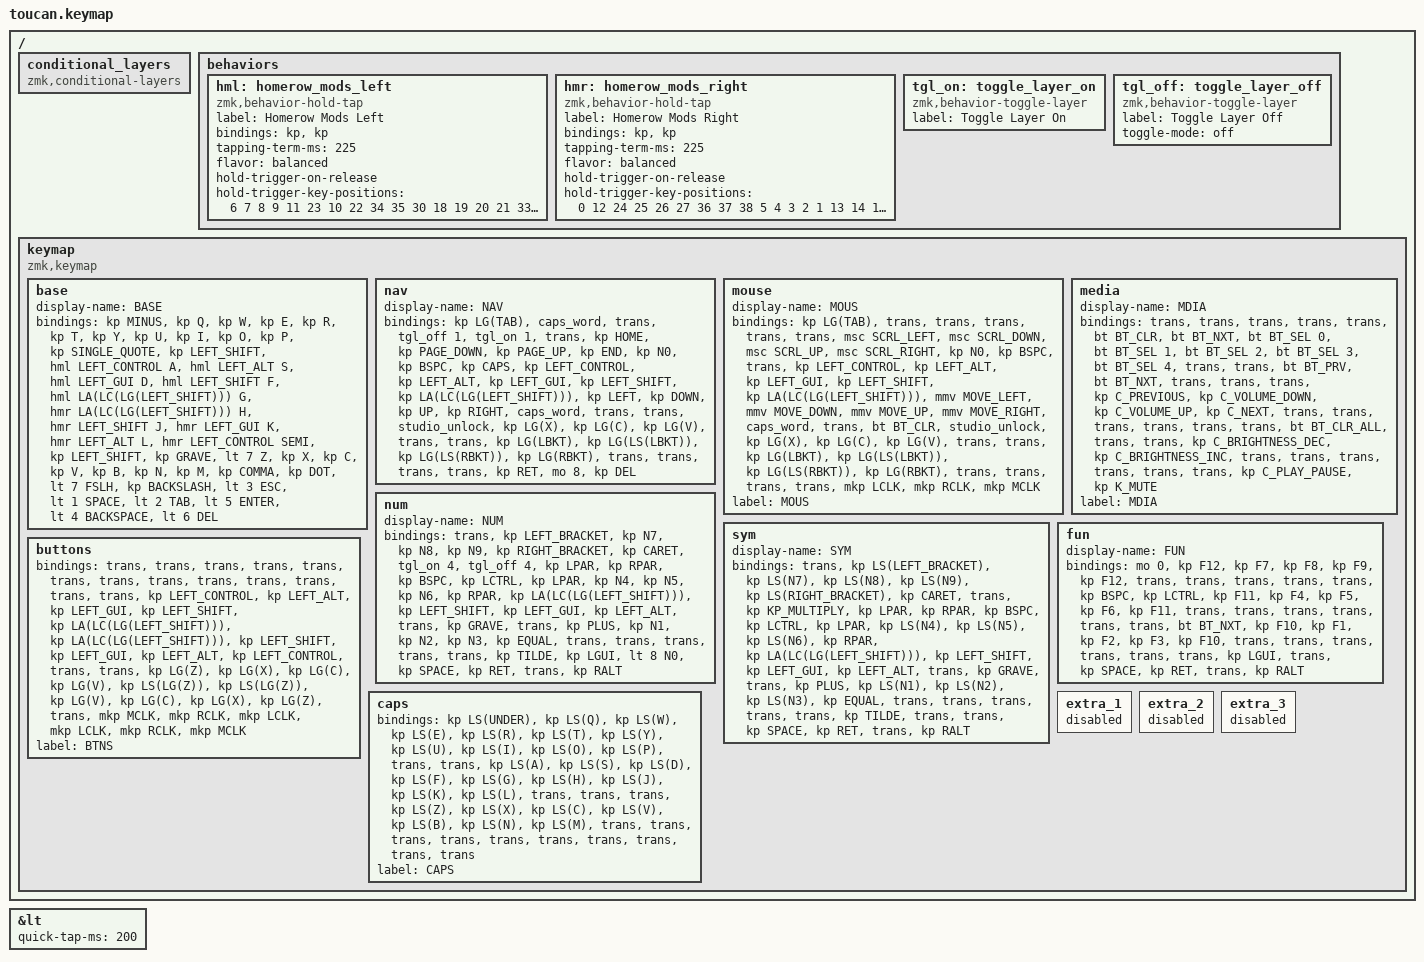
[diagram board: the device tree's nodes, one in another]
#include <behaviors.dtsi>
#include <dt-bindings/zmk/keys.h>
#include <dt-bindings/zmk/bt.h>
#include <dt-bindings/zmk/outputs.h>
#include <dt-bindings/zmk/pointing.h>

#define BASE 0
#define NAV  1
#define SYM  2
#define FUN  3

&lt {
    quick-tap-ms = <200>;
};

/ {
    conditional_layers { compatible = "zmk,conditional-layers"; };

    behaviors {
        hml: homerow_mods_left {
            compatible = "zmk,behavior-hold-tap";
            label = "Homerow Mods Left";
            bindings = <&kp>, <&kp>;

            #binding-cells = <2>;
            tapping-term-ms = <225>;
            flavor = "balanced";
            hold-trigger-on-release;
            hold-trigger-key-positions = <6 7 8 9 11 23 10 22 34 35 30 18 19 20 21 33 32 31 39 40 41 38 37>;
        };

        hmr: homerow_mods_right {
            compatible = "zmk,behavior-hold-tap";
            label = "Homerow Mods Right";
            bindings = <&kp>, <&kp>;

            #binding-cells = <2>;
            tapping-term-ms = <225>;
            flavor = "balanced";
            hold-trigger-on-release;
            hold-trigger-key-positions = <0 12 24 25 26 27 36 37 38 5 4 3 2 1 13 14 15 16 17 29 28>;
        };

        tgl_on: toggle_layer_on {
            compatible = "zmk,behavior-toggle-layer";
            label = "Toggle Layer On";
            #binding-cells = <1>;
        };

        tgl_off: toggle_layer_off {
            compatible = "zmk,behavior-toggle-layer";
            label = "Toggle Layer Off";
            #binding-cells = <1>;
            toggle-mode = "off";
        };
    };

    keymap {
        compatible = "zmk,keymap";

        base {
            display-name = "BASE";
            bindings = <
&kp MINUS  &kp Q  &kp W  &kp E  &kp R  &kp T  &kp Y  &kp U  &kp I  &kp O  &kp P  &kp SINGLE_QUOTE  &kp LEFT_SHIFT  &hml LEFT_CONTROL A  &hml LEFT_ALT S  &hml LEFT_GUI D  &hml LEFT_SHIFT F  &hml LA(LC(LG(LEFT_SHIFT))) G  &hmr LA(LC(LG(LEFT_SHIFT))) H  &hmr LEFT_SHIFT J  &hmr LEFT_GUI K  &hmr LEFT_ALT L  &hmr LEFT_CONTROL SEMI  &kp LEFT_SHIFT  &kp GRAVE  &lt 7 Z  &kp X  &kp C  &kp V  &kp B  &kp N  &kp M  &kp COMMA  &kp DOT  &lt 7 FSLH  &kp BACKSLASH  &lt 3 ESC  &lt 1 SPACE  &lt 2 TAB  &lt 5 ENTER  &lt 4 BACKSPACE  &lt 6 DEL
            >;
        };

        nav {
            display-name = "NAV";
            bindings = <
&kp LG(TAB)  &caps_word  &trans  &tgl_off 1  &tgl_on 1  &trans  &kp HOME  &kp PAGE_DOWN  &kp PAGE_UP  &kp END  &kp N0  &kp BSPC  &kp CAPS  &kp LEFT_CONTROL  &kp LEFT_ALT  &kp LEFT_GUI  &kp LEFT_SHIFT  &kp LA(LC(LG(LEFT_SHIFT)))  &kp LEFT  &kp DOWN  &kp UP  &kp RIGHT  &caps_word  &trans  &trans  &studio_unlock  &kp LG(X)  &kp LG(C)  &kp LG(V)  &trans  &trans  &kp LG(LBKT)  &kp LG(LS(LBKT))  &kp LG(LS(RBKT))  &kp LG(RBKT)  &trans  &trans  &trans  &trans  &kp RET  &mo 8  &kp DEL
            >;
        };

        mouse {
            display-name = "MOUS";
            bindings = <
&kp LG(TAB)  &trans  &trans  &trans  &trans  &trans  &msc SCRL_LEFT  &msc SCRL_DOWN  &msc SCRL_UP  &msc SCRL_RIGHT  &kp N0  &kp BSPC  &trans  &kp LEFT_CONTROL  &kp LEFT_ALT  &kp LEFT_GUI  &kp LEFT_SHIFT  &kp LA(LC(LG(LEFT_SHIFT)))  &mmv MOVE_LEFT  &mmv MOVE_DOWN  &mmv MOVE_UP  &mmv MOVE_RIGHT  &caps_word  &trans  &bt BT_CLR  &studio_unlock  &kp LG(X)  &kp LG(C)  &kp LG(V)  &trans  &trans  &kp LG(LBKT)  &kp LG(LS(LBKT))  &kp LG(LS(RBKT))  &kp LG(RBKT)  &trans  &trans  &trans  &trans  &mkp LCLK  &mkp RCLK  &mkp MCLK
            >;

            label = "MOUS";
        };

        media {
            display-name = "MDIA";
            bindings = <
&trans  &trans  &trans  &trans  &trans  &bt BT_CLR  &bt BT_NXT  &bt BT_SEL 0  &bt BT_SEL 1  &bt BT_SEL 2  &bt BT_SEL 3  &bt BT_SEL 4  &trans  &trans  &bt BT_PRV  &bt BT_NXT  &trans  &trans  &trans  &kp C_PREVIOUS  &kp C_VOLUME_DOWN  &kp C_VOLUME_UP  &kp C_NEXT  &trans  &trans  &trans  &trans  &trans  &trans  &bt BT_CLR_ALL  &trans  &trans  &kp C_BRIGHTNESS_DEC  &kp C_BRIGHTNESS_INC  &trans  &trans  &trans  &trans  &trans  &trans  &kp C_PLAY_PAUSE  &kp K_MUTE
            >;

            label = "MDIA";
        };

        num {
            display-name = "NUM";
            bindings = <
&trans  &kp LEFT_BRACKET  &kp N7  &kp N8  &kp N9  &kp RIGHT_BRACKET  &kp CARET  &tgl_on 4  &tgl_off 4  &kp LPAR  &kp RPAR  &kp BSPC  &kp LCTRL  &kp LPAR  &kp N4  &kp N5  &kp N6  &kp RPAR  &kp LA(LC(LG(LEFT_SHIFT)))  &kp LEFT_SHIFT  &kp LEFT_GUI  &kp LEFT_ALT  &trans  &kp GRAVE  &trans  &kp PLUS  &kp N1  &kp N2  &kp N3  &kp EQUAL  &trans  &trans  &trans  &trans  &trans  &kp TILDE  &kp LGUI  &lt 8 N0  &kp SPACE  &kp RET  &trans  &kp RALT
            >;
        };

        sym {
            display-name = "SYM";
            bindings = <
&trans  &kp LS(LEFT_BRACKET)  &kp LS(N7)  &kp LS(N8)  &kp LS(N9)  &kp LS(RIGHT_BRACKET)  &kp CARET  &trans  &kp KP_MULTIPLY  &kp LPAR  &kp RPAR  &kp BSPC  &kp LCTRL  &kp LPAR  &kp LS(N4)  &kp LS(N5)  &kp LS(N6)  &kp RPAR  &kp LA(LC(LG(LEFT_SHIFT)))  &kp LEFT_SHIFT  &kp LEFT_GUI  &kp LEFT_ALT  &trans  &kp GRAVE  &trans  &kp PLUS  &kp LS(N1)  &kp LS(N2)  &kp LS(N3)  &kp EQUAL  &trans  &trans  &trans  &trans  &trans  &kp TILDE  &trans  &trans  &kp SPACE  &kp RET  &trans  &kp RALT
            >;
        };

        fun {
            display-name = "FUN";
            bindings = <
&mo 0  &kp F12  &kp F7  &kp F8  &kp F9  &kp F12  &trans  &trans  &trans  &trans  &trans  &kp BSPC  &kp LCTRL  &kp F11  &kp F4  &kp F5  &kp F6  &kp F11  &trans  &trans  &trans  &trans  &trans  &trans  &bt BT_NXT  &kp F10  &kp F1  &kp F2  &kp F3  &kp F10  &trans  &trans  &trans  &trans  &trans  &trans  &kp LGUI  &trans  &kp SPACE  &kp RET  &trans  &kp RALT
            >;
        };

        buttons {
            bindings = <
&trans  &trans  &trans  &trans  &trans  &trans  &trans  &trans  &trans  &trans  &trans  &trans  &trans  &kp LEFT_CONTROL  &kp LEFT_ALT  &kp LEFT_GUI  &kp LEFT_SHIFT  &kp LA(LC(LG(LEFT_SHIFT)))  &kp LA(LC(LG(LEFT_SHIFT)))  &kp LEFT_SHIFT  &kp LEFT_GUI  &kp LEFT_ALT  &kp LEFT_CONTROL  &trans  &trans  &kp LG(Z)  &kp LG(X)  &kp LG(C)  &kp LG(V)  &kp LS(LG(Z))  &kp LS(LG(Z))  &kp LG(V)  &kp LG(C)  &kp LG(X)  &kp LG(Z)  &trans  &mkp MCLK  &mkp RCLK  &mkp LCLK  &mkp LCLK  &mkp RCLK  &mkp MCLK
            >;

            label = "BTNS";
        };

        caps {
            bindings = <
&kp LS(UNDER)  &kp LS(Q)  &kp LS(W)  &kp LS(E)  &kp LS(R)  &kp LS(T)  &kp LS(Y)  &kp LS(U)  &kp LS(I)  &kp LS(O)  &kp LS(P)  &trans  &trans  &kp LS(A)  &kp LS(S)  &kp LS(D)  &kp LS(F)  &kp LS(G)  &kp LS(H)  &kp LS(J)  &kp LS(K)  &kp LS(L)  &trans  &trans  &trans  &kp LS(Z)  &kp LS(X)  &kp LS(C)  &kp LS(V)  &kp LS(B)  &kp LS(N)  &kp LS(M)  &trans  &trans  &trans  &trans  &trans  &trans  &trans  &trans  &trans  &trans
            >;

            label = "CAPS";
        };

        extra_1 { status = "reserved"; };

        extra_2 { status = "reserved"; };

        extra_3 { status = "reserved"; };
    };
};
